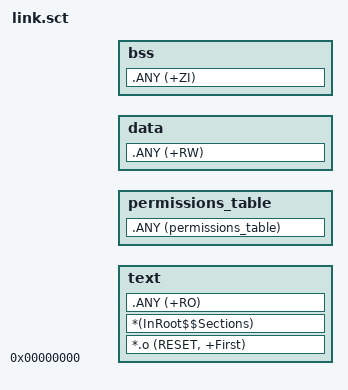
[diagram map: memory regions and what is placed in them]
; *************************************************************
; *** Scatter-Loading Description File generated by uVision ***
; *************************************************************

; load      region
LR_IROM1    (0x00000000)  PI
{
    text    +0;RIGION NAME
    {
        *.o (RESET, +First)
        *(InRoot$$Sections)
        .ANY (+RO)
    }

    permissions_table +0 ALIGN 4
    {
        .ANY (permissions_table)
    }

    data +0 ALIGN 4
    {
        .ANY (+RW)
    }

    bss +0
    {
        .ANY (+ZI)
    }
}

